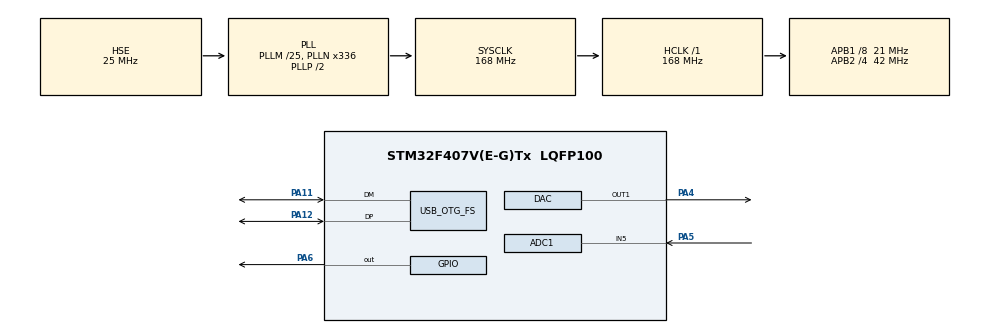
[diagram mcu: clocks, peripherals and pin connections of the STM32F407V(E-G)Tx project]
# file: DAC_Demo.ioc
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ADC1.Channel-0\#ChannelRegularConversion=ADC_CHANNEL_5
ADC1.ClockPrescaler=ADC_CLOCK_SYNC_PCLK_DIV2
ADC1.ContinuousConvMode=ENABLE
ADC1.DMAContinuousRequests=DISABLE
ADC1.EOCSelection=ADC_EOC_SEQ_CONV
ADC1.NbrOfConversionFlag=1
ADC1.Rank-0\#ChannelRegularConversion=1
ADC1.SamplingTime-0\#ChannelRegularConversion=ADC_SAMPLETIME_3CYCLES
ADC1.ScanConvMode=DISABLE
ADC1.master=1
DAC.DAC_OutputBuffer=DAC_OUTPUTBUFFER_ENABLE
DAC.DAC_Trigger=DAC_TRIGGER_T6_TRGO
Dma.DAC1.0.Direction=DMA_MEMORY_TO_PERIPH
Dma.DAC1.0.FIFOMode=DMA_FIFOMODE_DISABLE
Dma.DAC1.0.Instance=DMA1_Stream5
Dma.DAC1.0.MemDataAlignment=DMA_MDATAALIGN_HALFWORD
Dma.DAC1.0.MemInc=DMA_MINC_ENABLE
Dma.DAC1.0.Mode=DMA_CIRCULAR
Dma.DAC1.0.PeriphDataAlignment=DMA_PDATAALIGN_HALFWORD
Dma.DAC1.0.PeriphInc=DMA_PINC_DISABLE
Dma.DAC1.0.Priority=DMA_PRIORITY_MEDIUM
Dma.Request0=DAC1
Mcu.Family=STM32F4
Mcu.Name=STM32F407V(E-G)Tx
Mcu.Package=LQFP100
NVIC.ADC_IRQn=true\:0\:0\:false\:false\:true\:true\:true\:true
NVIC.DMA1_Stream5_IRQn=true\:0\:0\:false\:false\:true\:false\:true\:true
NVIC.OTG_FS_IRQn=true\:0\:0\:false\:false\:true\:true\:true\:true
NVIC.PriorityGroup=NVIC_PRIORITYGROUP_4
NVIC.TIM2_IRQn=true\:0\:0\:false\:false\:true\:true\:true\:true
NVIC.TIM6_DAC_IRQn=true\:0\:0\:false\:false\:true\:true\:true\:true
PA11.Mode=Device_Only
PA11.Signal=USB_OTG_FS_DM
PA12.Mode=Device_Only
PA12.Signal=USB_OTG_FS_DP
PA13.Mode=JTAG_4_pins
PA13.Signal=SYS_JTMS-SWDIO
PA14.Mode=JTAG_4_pins
PA14.Signal=SYS_JTCK-SWCLK
PA15.Mode=JTAG_4_pins
PA15.Signal=SYS_JTDI
PA4.Signal=COMP_DAC1_group
PA5.Signal=ADCx_IN5
PA6.GPIO_Speed=GPIO_SPEED_FREQ_VERY_HIGH
PA6.Signal=GPIO_Output
PB3.Mode=JTAG_4_pins
PB3.Signal=SYS_JTDO-SWO
PC14-OSC32_IN.Mode=LSE-External-Oscillator
PC14-OSC32_IN.Signal=RCC_OSC32_IN
PC15-OSC32_OUT.Mode=LSE-External-Oscillator
PC15-OSC32_OUT.Signal=RCC_OSC32_OUT
PH0-OSC_IN.Mode=HSE-External-Oscillator
PH0-OSC_IN.Signal=RCC_OSC_IN
PH1-OSC_OUT.Mode=HSE-External-Oscillator
PH1-OSC_OUT.Signal=RCC_OSC_OUT
ProjectManager.HeapSize=0x200
ProjectManager.StackSize=0x400
ProjectManager.TargetToolchain=STM32CubeIDE
RCC.48MHZClocksFreq_Value=48000000
RCC.AHBFreq_Value=168000000
RCC.APB1CLKDivider=RCC_HCLK_DIV8
RCC.APB1Freq_Value=21000000
RCC.APB1TimFreq_Value=42000000
RCC.APB2CLKDivider=RCC_HCLK_DIV4
RCC.APB2Freq_Value=42000000
RCC.APB2TimFreq_Value=84000000
RCC.CortexFreq_Value=168000000
RCC.HCLKFreq_Value=168000000
RCC.HSE_VALUE=25000000
RCC.HSI_VALUE=16000000
RCC.PLLM=25
RCC.PLLN=336
RCC.PLLQ=7
RCC.SYSCLKFreq_VALUE=168000000
RCC.SYSCLKSource=RCC_SYSCLKSOURCE_PLLCLK
RCC.VCOOutputFreq_Value=336000000
SH.ADCx_IN5.0=ADC1_IN5,IN5
SH.COMP_DAC1_group.0=DAC_OUT1,DAC_OUT1
TIM2.AutoReloadPreload=TIM_AUTORELOAD_PRELOAD_ENABLE
TIM2.Period=50-1
TIM2.Prescaler=42
TIM6.AutoReloadPreload=TIM_AUTORELOAD_PRELOAD_ENABLE
TIM6.Period=50-1
TIM6.Prescaler=42
TIM6.TIM_MasterOutputTrigger=TIM_TRGO_UPDATE
USB_DEVICE.CLASS_NAME_FS=CDC
USB_DEVICE.VirtualMode-CDC_FS=Cdc
USB_DEVICE.VirtualModeFS=Cdc_FS
USB_OTG_FS.VirtualMode=Device_Only
VP_TIM2_VS_ClockSourceINT.Mode=Internal
VP_TIM6_VS_ClockSourceINT.Mode=Enable_Timer
VP_USB_DEVICE_VS_USB_DEVICE_CDC_FS.Mode=CDC_FS
board=custom

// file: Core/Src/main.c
/* USER CODE BEGIN Header */
/**
  ******************************************************************************
  * @file           : main.c
  * @brief          : Main program body
  ******************************************************************************
  * @attention
  *
  * Copyright (c) 2024 STMicroelectronics.
  * All rights reserved.
  *
  * This software is licensed under terms that can be found in the LICENSE file
  * in the root directory of this software component.
  * If no LICENSE file comes with this software, it is provided AS-IS.
  *
  ******************************************************************************
  */
/* USER CODE END Header */
#include "main.h"
#include "adc.h"
#include "dac.h"
#include "dma.h"
#include "tim.h"
#include "usb_device.h"
#include "gpio.h"

/* USER CODE BEGIN PV */
uint16_t dac_data[DACVALUE_CNT] = {1208,1470,1703,1883,1990,2011,1946,1801,1592,1341,1076,825,616,471,
									406,427,534,714,947};
uint16_t adc_data;
//uint16_t dac_data[12] = {1246,1259,1261,1259,1246,1225,1204,1191,1189,1191,1204,1225};
/* USER CODE END PV */

void SystemClock_Config(void);

int main(void)
{

  /* MCU Configuration--------------------------------------------------------*/

  /* Reset of all peripherals, Initializes the Flash interface and the Systick. */
  HAL_Init();

  /* Configure the system clock */
  SystemClock_Config();

  /* Initialize all configured peripherals */
  MX_GPIO_Init();
  MX_DMA_Init();
  MX_DAC_Init();
  MX_TIM6_Init();
  MX_ADC1_Init();
  MX_USB_DEVICE_Init();
  MX_TIM2_Init();
  /* USER CODE BEGIN 2 */
  HAL_TIM_Base_Start(&htim6);
  HAL_DAC_Start_DMA(&hdac, DAC_CHANNEL_1, (uint32_t*)dac_data, DACVALUE_CNT ,DAC_ALIGN_12B_R);
  HAL_ADC_Start_IT(&hadc1);
  HAL_TIM_Base_Start_IT(&htim2);
  /* USER CODE END 2 */

  /* Infinite loop */
  while (1)
  {

  }
}

void SystemClock_Config(void)
{
  RCC_OscInitTypeDef RCC_OscInitStruct = {0};
  RCC_ClkInitTypeDef RCC_ClkInitStruct = {0};

  /** Configure the main internal regulator output voltage
  */
  __HAL_RCC_PWR_CLK_ENABLE();
  __HAL_PWR_VOLTAGESCALING_CONFIG(PWR_REGULATOR_VOLTAGE_SCALE1);

  /** Initializes the RCC Oscillators according to the specified parameters
  * in the RCC_OscInitTypeDef structure.
  */
  RCC_OscInitStruct.OscillatorType = RCC_OSCILLATORTYPE_HSE;
  RCC_OscInitStruct.HSEState = RCC_HSE_ON;
  RCC_OscInitStruct.PLL.PLLState = RCC_PLL_ON;
  RCC_OscInitStruct.PLL.PLLSource = RCC_PLLSOURCE_HSE;
  RCC_OscInitStruct.PLL.PLLM = 25;
  RCC_OscInitStruct.PLL.PLLN = 336;
  RCC_OscInitStruct.PLL.PLLP = RCC_PLLP_DIV2;
  RCC_OscInitStruct.PLL.PLLQ = 7;
  if (HAL_RCC_OscConfig(&RCC_OscInitStruct) != HAL_OK)
  {
    Error_Handler();
  }

  /** Initializes the CPU, AHB and APB buses clocks
  */
  RCC_ClkInitStruct.ClockType = RCC_CLOCKTYPE_HCLK|RCC_CLOCKTYPE_SYSCLK
                              |RCC_CLOCKTYPE_PCLK1|RCC_CLOCKTYPE_PCLK2;
  RCC_ClkInitStruct.SYSCLKSource = RCC_SYSCLKSOURCE_PLLCLK;
  RCC_ClkInitStruct.AHBCLKDivider = RCC_SYSCLK_DIV1;
  RCC_ClkInitStruct.APB1CLKDivider = RCC_HCLK_DIV8;
  RCC_ClkInitStruct.APB2CLKDivider = RCC_HCLK_DIV4;

  if (HAL_RCC_ClockConfig(&RCC_ClkInitStruct, FLASH_LATENCY_5) != HAL_OK)
  {
    Error_Handler();
  }
}

/* USER CODE BEGIN 4 */
void HAL_TIM_PeriodElapsedCallback(TIM_HandleTypeDef *htim)
{
	if(htim->Instance == TIM2)
	{
		adc_data = HAL_ADC_GetValue(&hadc1);
		HAL_GPIO_TogglePin(GPIOA, GPIO_PIN_6);
	}

}
/* USER CODE END 4 */

void Error_Handler(void)
{
  __disable_irq();
  while (1)
  {
  }
}
